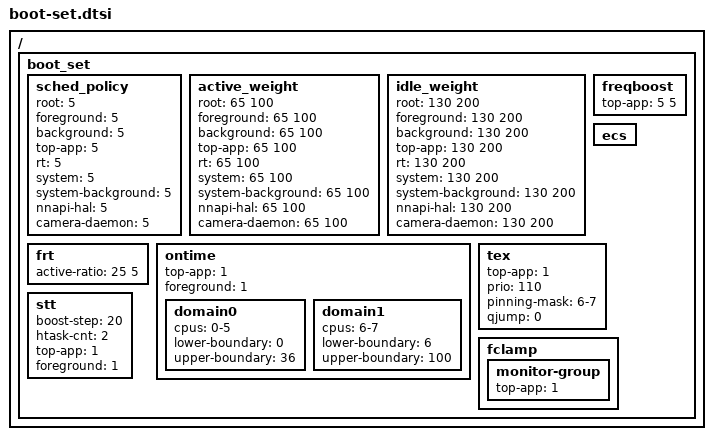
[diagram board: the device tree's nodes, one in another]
/ {
	boot_set: boot_set {
		sched_policy {
			root = <5>;
			foreground = <5>;
			background = <5>;
			top-app = <5>;
			rt = <5>;
			system = <5>;
			system-background = <5>;
			nnapi-hal = <5>;
			camera-daemon = <5>;
		};

		active_weight {
			root = <65 100>;
			foreground = <65 100>;
			background = <65 100>;
			top-app = <65 100>;
			rt = <65 100>;
			system = <65 100>;
			system-background = <65 100>;
			nnapi-hal = <65 100>;
			camera-daemon = <65 100>;
		};

		idle_weight {
			root = <130 200>;
			foreground = <130 200>;
			background = <130 200>;
			top-app = <130 200>;
			rt = <130 200>;
			system = <130 200>;
			system-background = <130 200>;
			nnapi-hal = <130 200>;
			camera-daemon = <130 200>;
		};

		freqboost {
			top-app = <5 5>;
		};

		frt {
			active-ratio = <25 5>;
		};

		ontime {
			top-app = <1>;
			foreground = <1>;

			domain0 {
				cpus = "0-5";
				lower-boundary = <0>;
				upper-boundary = <36>;
			};
			domain1 {
				cpus = "6-7";
				lower-boundary = <6>;
				upper-boundary = <100>;
			};
		};

		ecs { };

		tex {
			top-app = <1>;
			prio = <110>;
			pinning-mask = "6-7";
			qjump = <0>;
		};

		stt {
			boost-step = <20>;
			htask-cnt = <2>;
			top-app = <1>;
			foreground = <1>;
		};

		fclamp {
			monitor-group {
				top-app         = <1>;
			};
		};
	};
};
